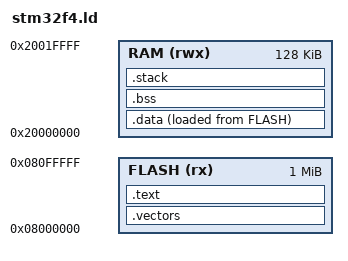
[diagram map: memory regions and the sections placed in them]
/* Linker script for STM32F4 (Renode) */
MEMORY {
    FLASH (rx)  : ORIGIN = 0x08000000, LENGTH = 1024K
    RAM   (rwx) : ORIGIN = 0x20000000, LENGTH = 128K
}

SECTIONS {
    .vectors : {
        KEEP(*(.vectors))
    } > FLASH

    .text : {
        *(.text*)
        *(.rodata*)
    } > FLASH

    .data : {
        *(.data*)
    } > RAM AT > FLASH

    .bss : {
        *(.bss*)
        *(COMMON)
    } > RAM

    .stack : {
        *(.stack)
    } > RAM

    /DISCARD/ : {
        *(.ARM.*)
        *(.comment)
    }
}
